# PKP register map
Registers from a debugger description file.
Registers are 32-bit, access not given, no defined reset value unless marked. A register's access mark holds for its fields unless they carry their own. Addresses are absolute; registers are grouped by the start of their names; lines under a group give offsets from that group; [hi:lo] are bit positions; {n}, {i} and the like mark numbered series; 'fields as' and 'values as' point back to an identical list; <NAME> marks a mode.

## TRNG
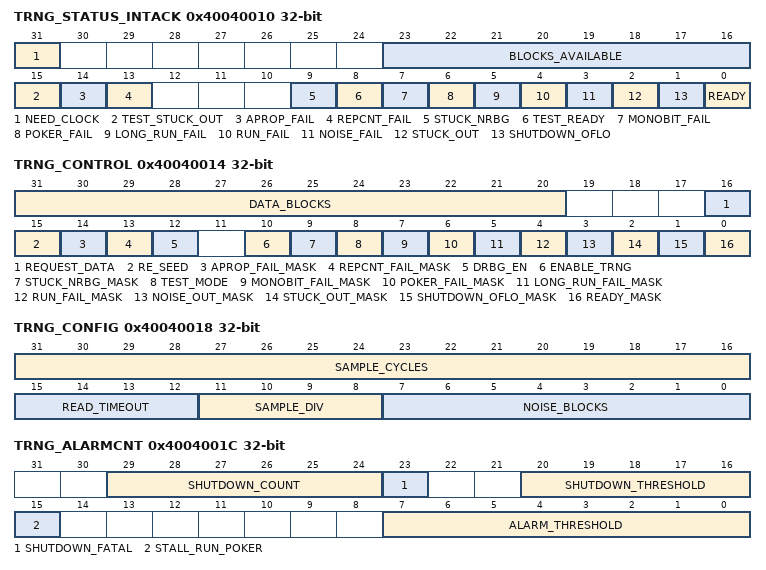
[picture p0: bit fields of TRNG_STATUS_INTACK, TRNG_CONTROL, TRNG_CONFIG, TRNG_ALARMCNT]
0x40040010 TRNG_STATUS_INTACK
  [31] NEED_CLOCK, [23:16] BLOCKS_AVAILABLE, [15] TEST_STUCK_OUT, [14] APROP_FAIL, [13] REPCNT_FAIL, [9] STUCK_NRBG, [8] TEST_READY, [7] MONOBIT_FAIL, [6] POKER_FAIL, [5] LONG_RUN_FAIL, [4] RUN_FAIL, [3] NOISE_FAIL, [2] STUCK_OUT, [1] SHUTDOWN_OFLO, [0] READY
0x40040014 TRNG_CONTROL
  [31:20] DATA_BLOCKS, [16] REQUEST_DATA, [15] RE_SEED, [14] APROP_FAIL_MASK, [13] REPCNT_FAIL_MASK, [12] DRBG_EN, [10] ENABLE_TRNG, [9] STUCK_NRBG_MASK, [8] TEST_MODE, [7] MONOBIT_FAIL_MASK, [6] POKER_FAIL_MASK, [5] LONG_RUN_FAIL_MASK, [4] RUN_FAIL_MASK, [3] NOISE_OUT_MASK, [2] STUCK_OUT_MASK, [1] SHUTDOWN_OFLO_MASK, [0] READY_MASK
0x40040018 TRNG_CONFIG
  [31:16] SAMPLE_CYCLES, [15:12] READ_TIMEOUT, [11:8] SAMPLE_DIV, [7:0] NOISE_BLOCKS
0x4004001C TRNG_ALARMCNT
  [29:24] SHUTDOWN_COUNT, [23] SHUTDOWN_FATAL, [20:16] SHUTDOWN_THRESHOLD, [15] STALL_RUN_POKER, [7:0] ALARM_THRESHOLD
0x40040020 TRNG_FROENABLE
  [23:0] FRO_ENABLES
0x40040024 TRNG_FRODETUNE
  [23:0] FRO_DETUNES
0x40040028 TRNG_ALARMMASK
  [23:0] FRO_ALARMMASK
0x4004002C TRNG_ALARMSTOP
  [23:0] FRO_ALARMSTOP
0x40040030 TRNG_RAW_L
  [31:0] SHIFT_REG_0
0x40040034 TRNG_RAW_H
  [31:0] SHIFT_REG_1
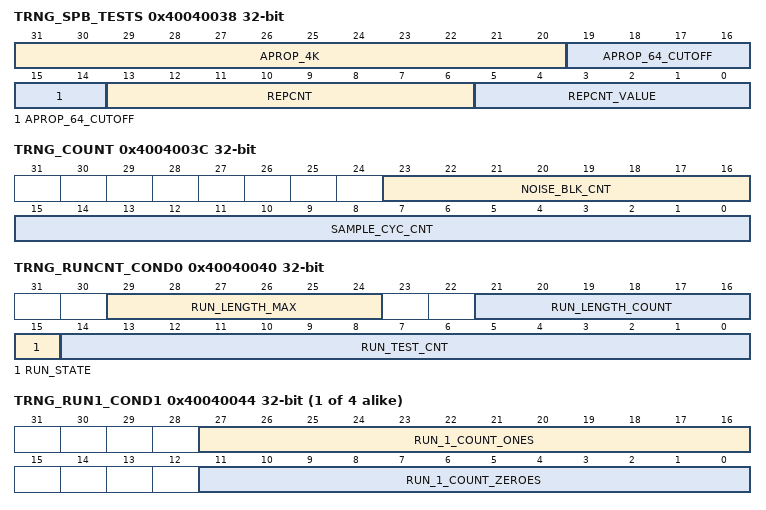
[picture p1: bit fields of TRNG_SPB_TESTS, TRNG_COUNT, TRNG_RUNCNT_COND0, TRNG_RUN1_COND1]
0x40040038 TRNG_SPB_TESTS
  [31:20] APROP_4K, [19:14] APROP_64_CUTOFF, [13:6] REPCNT, [5:0] REPCNT_VALUE
0x4004003C TRNG_COUNT
  [23:16] NOISE_BLK_CNT, [15:0] SAMPLE_CYC_CNT
0x40040040 TRNG_RUNCNT_COND0
  [29:24] RUN_LENGTH_MAX, [21:16] RUN_LENGTH_COUNT, [15] RUN_STATE, [14:0] RUN_TEST_CNT
{0x40040040+4i} TRNG_RUN{i}_COND{i} (i=1..4)
  [{28-i}:16] RUN_{i}_COUNT_ONES, [{12-i}:0] RUN_{i}_COUNT_ZEROES
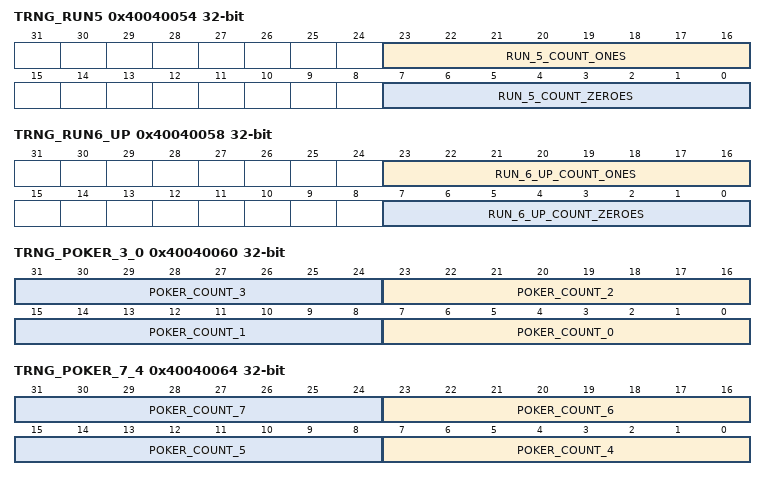
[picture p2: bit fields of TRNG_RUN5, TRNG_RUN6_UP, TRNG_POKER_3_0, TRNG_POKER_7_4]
0x40040054 TRNG_RUN5 ro
  [23:16] RUN_5_COUNT_ONES, [7:0] RUN_5_COUNT_ZEROES
0x40040058 TRNG_RUN6_UP ro
  [23:16] RUN_6_UP_COUNT_ONES, [7:0] RUN_6_UP_COUNT_ZEROES
0x4004005C TRNG_MONOBITCNT ro
  [16:0] MONOBIT_COUNT
0x40040060 TRNG_POKER_3_0 ro
  [8n+7:8n] POKER_COUNT_{n} (n=0..3)
0x40040064 TRNG_POKER_7_4 ro
  [8n-25:8n-32] POKER_COUNT_{n} (n=4..7)
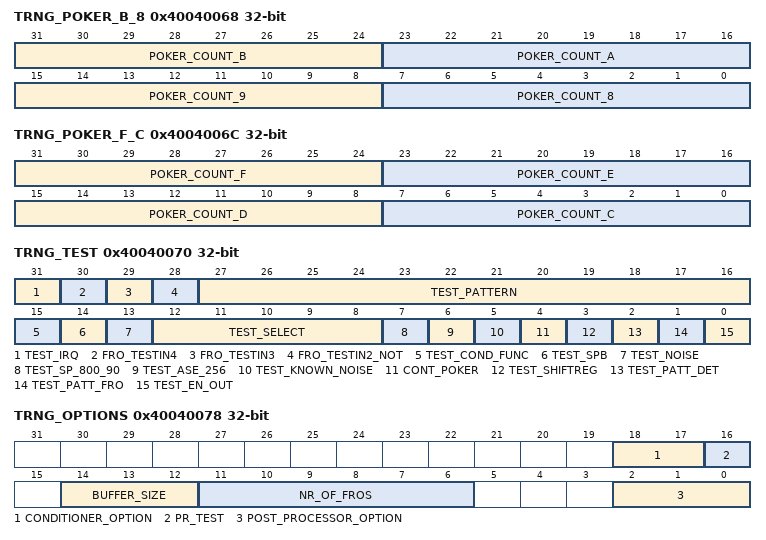
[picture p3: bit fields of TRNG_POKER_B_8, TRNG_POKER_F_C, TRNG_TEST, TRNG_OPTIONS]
0x40040068 TRNG_POKER_B_8 ro
  [31:24] POKER_COUNT_B, [23:16] POKER_COUNT_A, [15:8] POKER_COUNT_9, [7:0] POKER_COUNT_8
0x4004006C TRNG_POKER_F_C ro
  [31:24] POKER_COUNT_F, [23:16] POKER_COUNT_E, [15:8] POKER_COUNT_D, [7:0] POKER_COUNT_C
0x40040070 TRNG_TEST
  [31] TEST_IRQ, [30] FRO_TESTIN4, [29] FRO_TESTIN3, [28] FRO_TESTIN2_NOT, [27:16] TEST_PATTERN, [15] TEST_COND_FUNC, [14] TEST_SPB, [13] TEST_NOISE, [12:8] TEST_SELECT, [7] TEST_SP_800_90, [6] TEST_ASE_256, [5] TEST_KNOWN_NOISE, [4] CONT_POKER, [3] TEST_SHIFTREG, [2] TEST_PATT_DET, [1] TEST_PATT_FRO, [0] TEST_EN_OUT
0x40040078 TRNG_OPTIONS ro
  [18:17] CONDITIONER_OPTION, [16] PR_TEST, [14:12] BUFFER_SIZE, [11:6] NR_OF_FROS, [2:0] POST_PROCESSOR_OPTION
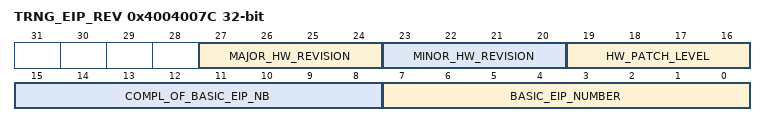
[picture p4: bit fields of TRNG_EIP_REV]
0x4004007C TRNG_EIP_REV ro
  [27:24] MAJOR_HW_REVISION, [23:20] MINOR_HW_REVISION, [19:16] HW_PATCH_LEVEL, [15:8] COMPL_OF_BASIC_EIP_NB, [7:0] BASIC_EIP_NUMBER

## PKA
0x40044000 PKA_APTR
  [10:0] APTR
0x40044004 PKA_BPTR
  [10:0] BPTR
0x40044008 PKA_CPTR
  [10:0] CPTR
0x4004400C PKA_DPTR
  [10:0] DPTR
0x40044010 PKA_ALENGTH
  [9:0] ALENGTH
0x40044014 PKA_BLENGTH
  [9:0] BLENGTH
0x40044018 PKA_SHIFT
  [4:0] BITS_TO_SHIFT
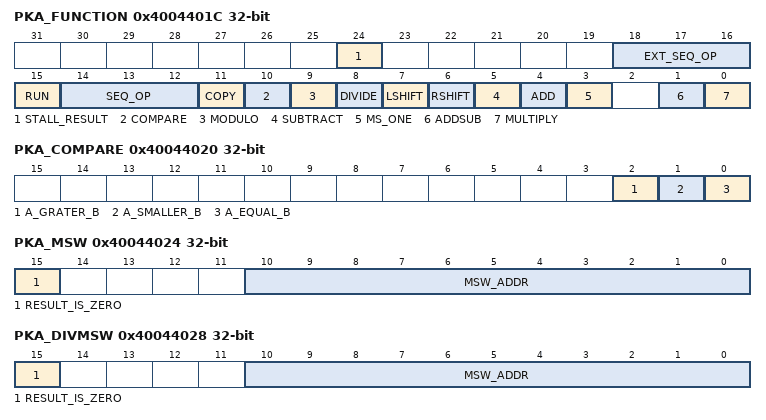
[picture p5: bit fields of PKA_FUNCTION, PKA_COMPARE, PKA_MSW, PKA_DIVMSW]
0x4004401C PKA_FUNCTION
  [24] STALL_RESULT, [18:16] EXT_SEQ_OP, [15] RUN, [14:12] SEQ_OP, [11] COPY, [10] COMPARE, [9] MODULO, [8] DIVIDE, [7] LSHIFT, [6] RSHIFT, [5] SUBTRACT, [4] ADD, [3] MS_ONE, [1] ADDSUB, [0] MULTIPLY
0x40044020 PKA_COMPARE ro
  [2] A_GRATER_B, [1] A_SMALLER_B, [0] A_EQUAL_B
0x40044024 PKA_MSW ro
  [15] RESULT_IS_ZERO, [10:0] MSW_ADDR
0x40044028 PKA_DIVMSW ro
  [15] RESULT_IS_ZERO, [10:0] MSW_ADDR
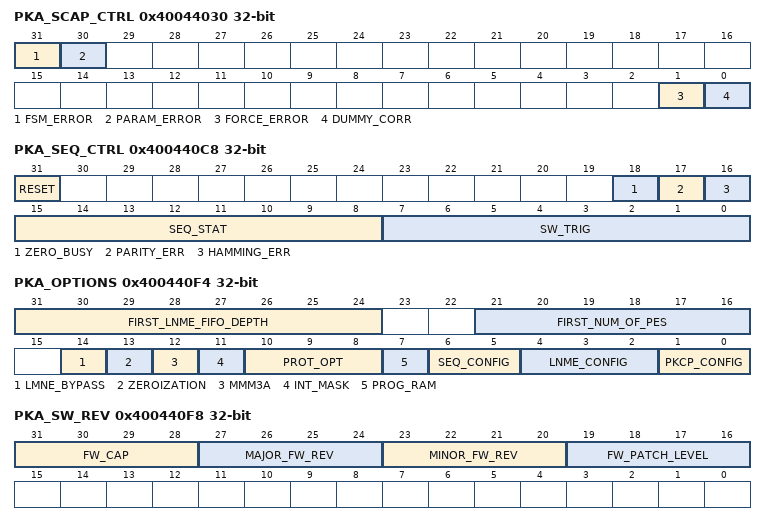
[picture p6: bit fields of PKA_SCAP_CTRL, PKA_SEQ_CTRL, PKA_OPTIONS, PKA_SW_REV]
0x40044030 PKA_SCAP_CTRL
  [31] FSM_ERROR, [30] PARAM_ERROR, [1] FORCE_ERROR, [0] DUMMY_CORR
0x400440C8 PKA_SEQ_CTRL
  [31] RESET, [18] ZERO_BUSY, [17] PARITY_ERR, [16] HAMMING_ERR, [15:8] SEQ_STAT, [7:0] SW_TRIG
0x400440F4 PKA_OPTIONS ro
  [31:24] FIRST_LNME_FIFO_DEPTH, [21:16] FIRST_NUM_OF_PES, [14] LMNE_BYPASS, [13] ZEROIZATION, [12] MMM3A, [11] INT_MASK, [10:8] PROT_OPT, [7] PROG_RAM, [6:5] SEQ_CONFIG, [4:2] LNME_CONFIG, [1:0] PKCP_CONFIG
0x400440F8 PKA_SW_REV ro
  [31:28] FW_CAP, [27:24] MAJOR_FW_REV, [23:20] MINOR_FW_REV, [19:16] FW_PATCH_LEVEL
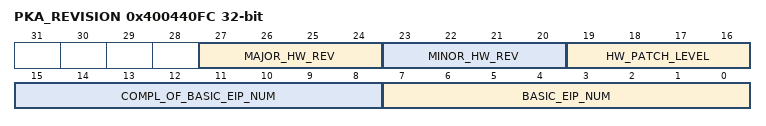
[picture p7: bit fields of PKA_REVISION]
0x400440FC PKA_REVISION ro
  [27:24] MAJOR_HW_REV, [23:20] MINOR_HW_REV, [19:16] HW_PATCH_LEVEL, [15:8] COMPL_OF_BASIC_EIP_NUM, [7:0] BASIC_EIP_NUM

## AIC
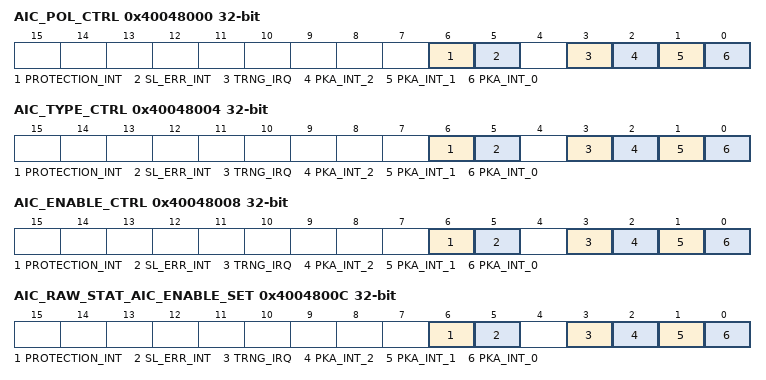
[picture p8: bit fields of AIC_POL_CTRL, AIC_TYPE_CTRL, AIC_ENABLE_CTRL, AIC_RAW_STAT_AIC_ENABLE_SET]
0x40048000 AIC_POL_CTRL ro
  [6] PROTECTION_INT, [5] SL_ERR_INT, [3] TRNG_IRQ, [2] PKA_INT_2, [1] PKA_INT_1, [0] PKA_INT_0
0x40048004 AIC_TYPE_CTRL ro
  fields as AIC_POL_CTRL
0x40048008 AIC_ENABLE_CTRL
  fields as AIC_POL_CTRL
0x4004800C AIC_RAW_STAT_AIC_ENABLE_SET
  fields as AIC_POL_CTRL
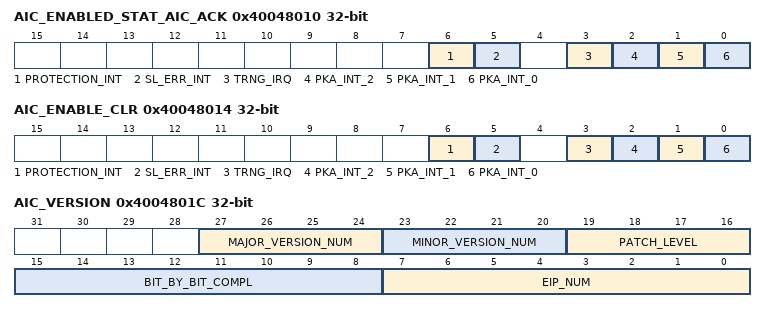
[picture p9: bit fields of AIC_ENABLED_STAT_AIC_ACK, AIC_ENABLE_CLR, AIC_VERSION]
0x40048010 AIC_ENABLED_STAT_AIC_ACK
  fields as AIC_POL_CTRL
0x40048014 AIC_ENABLE_CLR wo
  fields as AIC_POL_CTRL
0x40048018 AIC_OPTIONS ro
  [6:0] NUM_OF_INPUTS
0x4004801C AIC_VERSION ro
  [27:24] MAJOR_VERSION_NUM, [23:20] MINOR_VERSION_NUM, [19:16] PATCH_LEVEL, [15:8] BIT_BY_BIT_COMPL, [7:0] EIP_NUM

## EIP150
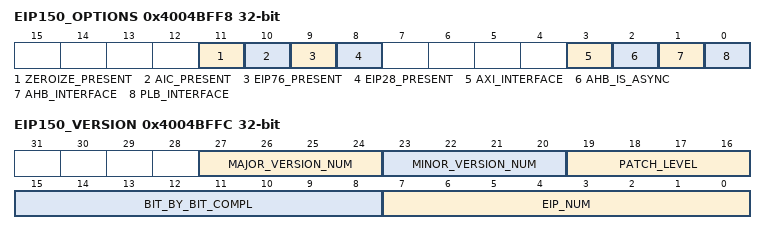
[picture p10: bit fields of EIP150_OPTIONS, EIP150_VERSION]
0x4004BFF8 EIP150_OPTIONS ro
  [11] ZEROIZE_PRESENT, [10] AIC_PRESENT, [9] EIP76_PRESENT, [8] EIP28_PRESENT, [3] AXI_INTERFACE, [2] AHB_IS_ASYNC, [1] AHB_INTERFACE, [0] PLB_INTERFACE
0x4004BFFC EIP150_VERSION ro
  [27:24] MAJOR_VERSION_NUM, [23:20] MINOR_VERSION_NUM, [19:16] PATCH_LEVEL, [15:8] BIT_BY_BIT_COMPL, [7:0] EIP_NUM
